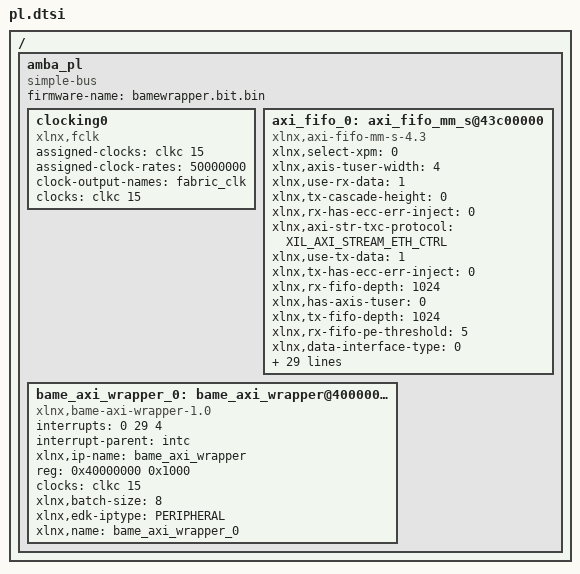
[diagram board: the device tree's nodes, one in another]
/ {
	amba_pl: amba_pl {
		ranges;
		compatible = "simple-bus";
		#address-cells = <1>;
		#size-cells = <1>;
		firmware-name = "bamewrapper.bit.bin";
		clocking0: clocking0 {
			compatible = "xlnx,fclk";
			assigned-clocks = <&clkc 15>;
			assigned-clock-rates = <50000000>;
			#clock-cells = <0>;
			clock-output-names = "fabric_clk";
			clocks = <&clkc 15>;
		};
		axi_fifo_0: axi_fifo_mm_s@43c00000 {
			xlnx,select-xpm = <0>;
			xlnx,axis-tuser-width = <4>;
			compatible = "xlnx,axi-fifo-mm-s-4.3" , "xlnx,axi-fifo-mm-s";
			xlnx,use-rx-data = <1>;
			xlnx,tx-cascade-height = <0>;
			xlnx,rx-has-ecc-err-inject = <0>;
			xlnx,axi-str-txc-protocol = "XIL_AXI_STREAM_ETH_CTRL";
			xlnx,use-tx-data = <1>;
			xlnx,tx-has-ecc-err-inject = <0>;
			xlnx,rx-fifo-depth = <1024>;
			xlnx,has-axis-tuser = <0>;
			xlnx,tx-fifo-depth = <1024>;
			xlnx,rx-fifo-pe-threshold = <5>;
			xlnx,data-interface-type = <0>;
			xlnx,ip-name = "axi_fifo_mm_s";
			xlnx,use-tx-ctrl = <1>;
			xlnx,rx-fifo-pf-threshold = <507>;
			xlnx,axis-tid-width = <4>;
			reg = <0x43c00000 0x10000>;
			clocks = <&clkc 15>;
			xlnx,tx-fifo-pe-threshold = <5>;
			xlnx,tx-fifo-pf-threshold = <507>;
			xlnx,s-axi4-data-width = <32>;
			xlnx,has-axis-tstrb = <0>;
			xlnx,axi-str-rxd-protocol = "XIL_AXI_STREAM_ETH_DATA";
			xlnx,use-rx-cut-through = <0>;
			xlnx,axi-str-rxd-tdata-width = <32>;
			xlnx,axis-tdest-width = <4>;
			xlnx,edk-iptype = "PERIPHERAL";
			xlnx,has-axis-tkeep = <0>;
			xlnx,has-axis-tid = <0>;
			xlnx,axi-str-txc-tdata-width = <32>;
			xlnx,axi-str-txd-protocol = "XIL_AXI_STREAM_ETH_DATA";
			xlnx,use-tx-cut-through = <0>;
			xlnx,axi-str-txd-tdata-width = <32>;
			xlnx,rx-enable-ecc = <0>;
			status = "okay";
			clock-names = "s_axi_aclk";
			xlnx,has-axis-tdest = <0>;
			xlnx,tx-enable-ecc = <0>;
			xlnx,s-axi-id-width = <4>;
			xlnx,rx-cascade-height = <0>;
			xlnx,name = "axi_fifo_0";
		};
		bame_axi_wrapper_0: bame_axi_wrapper@40000000 {
			compatible = "xlnx,bame-axi-wrapper-1.0";
			interrupts = < 0 29 4 >;
			interrupt-parent = <&intc>;
			xlnx,ip-name = "bame_axi_wrapper";
			reg = <0x40000000 0x1000>;
			clocks = <&clkc 15>;
			xlnx,batch-size = <8>;
			xlnx,edk-iptype = "PERIPHERAL";
			status = "okay";
			clock-names = "aclk";
			interrupt-names = "irq";
			xlnx,name = "bame_axi_wrapper_0";
		};
	};
};
